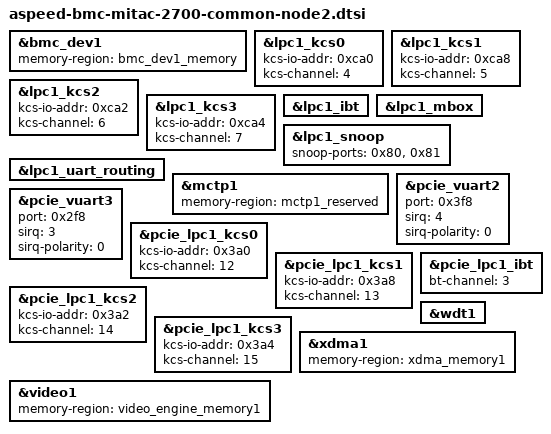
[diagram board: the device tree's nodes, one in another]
// SPDX-License-Identifier: GPL-2.0-or-later
// Copyright 2025 MiTAC-Computing Corp.

&bmc_dev1 {
	status = "okay";
	memory-region = <&bmc_dev1_memory>;
};

&lpc1_kcs0 {
	status = "okay";
	kcs-io-addr = <0xca0>;
	kcs-channel = <4>;
};

&lpc1_kcs1 {
	status = "okay";
	kcs-io-addr = <0xca8>;
	kcs-channel = <5>;
};

&lpc1_kcs2 {
	status = "okay";
	kcs-io-addr = <0xca2>;
	kcs-channel = <6>;
};

&lpc1_kcs3 {
	status = "okay";
	kcs-io-addr = <0xca4>;
	kcs-channel = <7>;
};

&lpc1_ibt {
	status = "okay";
};

&lpc1_mbox {
	status = "okay";
};

&lpc1_snoop {
	status = "okay";
	snoop-ports = <0x80>, <0x81>;
};

&lpc1_uart_routing {
	status = "okay";
};

&mctp1 {
	status = "okay";
	memory-region = <&mctp1_reserved>;
};

&pcie_vuart2 {
	port = <0x3f8>;
	sirq = <4>;
	sirq-polarity = <0>;

	status = "okay";
};

&pcie_vuart3 {
	port = <0x2f8>;
	sirq = <3>;
	sirq-polarity = <0>;

	status = "okay";
};

&pcie_lpc1_kcs0 {
	status = "okay";
	kcs-io-addr = <0x3a0>;
	kcs-channel = <12>;
};

&pcie_lpc1_kcs1 {
	status = "okay";
	kcs-io-addr = <0x3a8>;
	kcs-channel = <13>;
};

&pcie_lpc1_kcs2 {
	status = "okay";
	kcs-io-addr = <0x3a2>;
	kcs-channel = <14>;
};

&pcie_lpc1_kcs3 {
	status = "okay";
	kcs-io-addr = <0x3a4>;
	kcs-channel = <15>;
};

&pcie_lpc1_ibt {
	status = "okay";
	bt-channel = <3>;
};

&video1 {
	status = "okay";
	memory-region = <&video_engine_memory1>;
};

&wdt1 {
	status = "okay";
};

&xdma1 {
	status = "okay";
	memory-region = <&xdma_memory1>;
};
